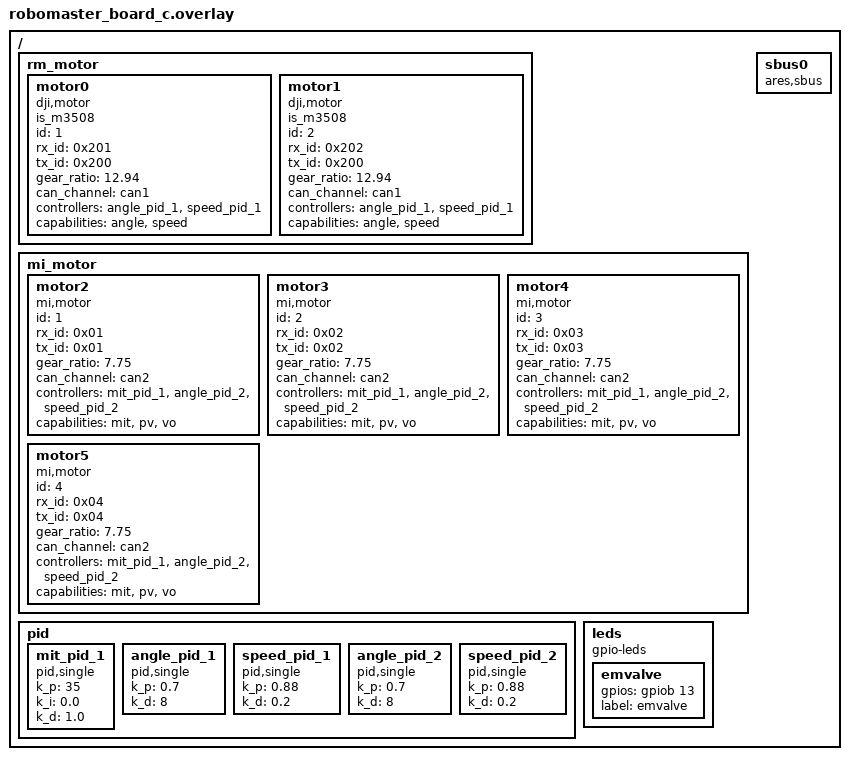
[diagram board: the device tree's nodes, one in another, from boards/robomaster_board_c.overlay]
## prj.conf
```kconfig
# 启用线程分析器
CONFIG_THREAD_ANALYZER=y
CONFIG_THREAD_ANALYZER_USE_LOG=y
CONFIG_THREAD_ANALYZER_USE_PRINTK=n
CONFIG_THREAD_NAME=y
# CONFIG_THREAD_ANALYZER_AUTO=y
# CONFIG_THREAD_ANALYZER_AUTO_INTERVAL=5
CONFIG_THREAD_ANALYZER_LOG_LEVEL_INF=y
CONFIG_THREAD_ANALYZER_AUTO_SEPARATE_CORES=n

# 启用 Shell 支持
CONFIG_SHELL=n
CONFIG_SHELL_BACKENDS=n
CONFIG_SHELL_BACKEND_SERIAL=n

# 启用 UART 控制台
CONFIG_UART_CONSOLE=y

# 禁用 SEGGER RTT
CONFIG_USE_SEGGER_RTT=n

# 启用事件支持
CONFIG_EVENTS=y

# 启用控制台支持
CONFIG_CONSOLE=y

# 启用串行支持
CONFIG_SERIAL=y
CONFIG_SPI_ASYNC=y
# 禁用优化
CONFIG_NO_OPTIMIZATIONS=y

# 启用驱动
CONFIG_MOTOR=y
CONFIG_MOTOR_DJI=y
CONFIG_MOTOR_MI=y
CONFIG_MOTOR_LOG_LEVEL=4
CONFIG_CAN=y
CONFIG_MOTOR_INIT_PRIORITY=90
CONFIG_PID=y

CONFIG_ARES=y
CONFIG_ARES_SBUS=y
CONFIG_SBUS_INIT_PRIORITY=90

# use ASYNC uart API
CONFIG_SERIAL=y
CONFIG_UART_ASYNC_API=y
CONFIG_UART_INTERRUPT_DRIVEN=y

CONFIG_DMA=y
CONFIG_DMA_STM32=y  # STM32 DMA 驱动
CONFIG_UART_STM32=y # STM32 UART 驱动
# CONFIG_STM32_UART_DMA=y

# CONFIG_HAS_STM32CUBE=y
# CONFIG_USE_STM32_HAL_DMA=y
# CONFIG_SPI=y
# CONFIG_SPI_STM32=y

#
# Device Drivers
#
# CONFIG_SENSOR=y
# CONFIG_BMI08X=y
# CONFIG_BMI08X_ACCEL_TRIGGER_NONE is not set
# CONFIG_BMI08X_ACCEL_TRIGGER_GLOBAL_THREAD=y
# CONFIG_BMI08X_ACCEL_TRIGGER_OWN_THREAD is not set
# CONFIG_BMI08X_GYRO_TRIGGER_NONE is not set
# CONFIG_BMI08X_GYRO_TRIGGER_GLOBAL_THREAD=y
# CONFIG_BMI08X_GYRO_TRIGGER_OWN_THREAD is not set
# CONFIG_BMI08X_I2C_WRITE_BURST_SIZE=16

CONFIG_DEBUG_THREAD_INFO=y

CONFIG_MAIN_STACK_SIZE=4096
```

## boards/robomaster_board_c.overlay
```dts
/ {
	rm_motor {
		motor0: motor0{
			compatible = "dji,motor";
            is_m3508;
			id = <1>;
            rx_id = <0x201>;
            tx_id = <0x200>;
			gear_ratio = "12.94";
			status = "okay";
			can_channel = <&can1>;
			controllers = <&angle_pid_1 &speed_pid_1>;
			capabilities = "angle", "speed";
		};

		motor1: motor1{
			compatible = "dji,motor";
            is_m3508;
			id = <2>;
            rx_id = <0x202>;
            tx_id = <0x200>;
			gear_ratio = "12.94";
			status = "okay";
			can_channel = <&can1>;
			controllers = <&angle_pid_1 &speed_pid_1>;
			capabilities = "angle", "speed";
		};
	};
	mi_motor{
		motor2: motor2{
			compatible = "mi,motor";
			id = <1>;
            rx_id = <0x01>;
            tx_id = <0x01>;
			gear_ratio = "7.75";
			status = "okay";

			can_channel = <&can2>;
			controllers = <&mit_pid_1 &angle_pid_2 &speed_pid_2>;
			capabilities = "mit", "pv", "vo";
		};
		motor3: motor3{
			compatible = "mi,motor";           
			id = <2>;
            rx_id = <0x02>;
            tx_id = <0x02>;
			gear_ratio = "7.75";
			status = "okay";
			can_channel = <&can2>;
			controllers = <&mit_pid_1 &angle_pid_2 &speed_pid_2>;
			capabilities = "mit", "pv", "vo";
		};
        motor4: motor4{
			compatible = "mi,motor";           
			id = <3>;
            rx_id = <0x03>;
            tx_id = <0x03>;
			gear_ratio = "7.75";
			status = "okay";
			can_channel = <&can2>;
			controllers = <&mit_pid_1 &angle_pid_2 &speed_pid_2>;
			capabilities = "mit", "pv", "vo";
		};
        motor5: motor5{
			compatible = "mi,motor";           
			id = <4>;
            rx_id = <0x04>;
            tx_id = <0x04>;
			gear_ratio = "7.75";
			status = "okay";
			can_channel = <&can2>;
			controllers = <&mit_pid_1 &angle_pid_2 &speed_pid_2>;
			capabilities = "mit", "pv", "vo";
		};
	};

	pid {
		mit_pid_1: mit_pid_1 {
			#controller-cells = <0>;
			compatible = "pid,single";
			k_p = "35";
			k_i = "0.0";
			k_d = "1.0";
		};
		angle_pid_1: angle_pid_1 {
			#controller-cells = <0>;
			compatible = "pid,single";
			k_p = "0.7";
			k_d = "8";
		};
		speed_pid_1: speed_pid_1 {
			#controller-cells = <0>;
			compatible = "pid,single";
			k_p = "0.88";
			k_d = "0.2";
		};
		angle_pid_2: angle_pid_2 {
			#controller-cells = <0>;
			compatible = "pid,single";
			k_p = "0.7";
			k_d = "8";
		};
		speed_pid_2: speed_pid_2 {
			#controller-cells = <0>;
			compatible = "pid,single";
			k_p = "0.88";
			k_d = "0.2";
		};
	};

leds {
    compatible = "gpio-leds";
    emvalve: emvalve {
        gpios = <&gpiob 13 GPIO_ACTIVE_HIGH>;
        label = "emvalve";
    };
};

	sbus0: sbus0 {
		compatible = "ares,sbus";
		status = "okay";
	};
};
```

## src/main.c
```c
#include "ares/board/init.h"
#include "ares/ares_comm.h"
#include <ares/protocol/dual/dual_protocol.h>
#include <ares/interface/usb/usb_bulk.h>
#include "R2_devices.h"
#include "five_linkage.h"
#include <stdbool.h>
#include <stddef.h>
#include <stdint.h>
#include <stdio.h>
#include <math.h>
#include <zephyr/logging/log.h>
#include <zephyr/devicetree.h>
#include <zephyr/drivers/can.h>
#include <zephyr/debug/thread_analyzer.h>
#include <zephyr/kernel.h>
#include <zephyr/sys/printk.h>
#include <zephyr/drivers/uart.h>
#include <zephyr/drivers/motor.h>
#include <zephyr/drivers/sbus.h>
#include <zephyr/drivers/sensor.h>

LOG_MODULE_REGISTER(main, LOG_LEVEL_DBG);

#define HIGH_BYTE(x) ((x) >> 8)
#define LOW_BYTE(x) ((x)&0xFF)
#define COMBINE_HL8(HIGH, LOW) ((HIGH << 8) + LOW)

struct k_thread feedback_thread_data;
k_tid_t feedback_tid = 0;
K_THREAD_STACK_DEFINE(feedback_stack_area, 4096);



Five link;

float Coordinates[2] = {0.0f, 0.0f}; //末端坐标

void rx_cb(void) {
    // 简单验证
    if (!isfinite(Coordinates[0]) || !isfinite(Coordinates[1])) {
        LOG_ERR("Invalid coordinates received");
        return;
    }
    
    // 执行控制
    go_to_position(&link, Coordinates[0], Coordinates[1]);
    
    // 日志输出（可选择降低频率）
    LOG_DBG("Coordinates: x=%.1f, y=%.1f", Coordinates[0], Coordinates[1]);
}

ARES_BULK_INTERFACE_DEFINE(usb_bulk_interface);
DUAL_PROPOSE_PROTOCOL_DEFINE(dual_protocol);
int main()
{ 

  five_init(&link, 230.0, 270.0, 270.0, 230.0, 200.0);
  ares_bind_interface(&usb_bulk_interface, &dual_protocol);

  dual_sync_add(&dual_protocol, 0x4004, (uint8_t *)Coordinates, sizeof(Coordinates), rx_cb);


  motor_set_mode(motor5,MIT);
  k_msleep(1);
  motor_set_mode(motor6,MIT);

  init_position();//电机编码初始化
  k_msleep(500);

  while(1)
  {
    k_msleep(1);
  }
}
```

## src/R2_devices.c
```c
#include "R2_devices.h"

const struct device *motor1 = DEVICE_DT_GET(MOTOR1_NODE);//3508
const struct device *motor2 = DEVICE_DT_GET(MOTOR2_NODE);//3508
const struct device *motor3 = DEVICE_DT_GET(MOTOR3_NODE);//运球mi
const struct device *motor4 = DEVICE_DT_GET(MOTOR4_NODE);//运球mi
const struct device *motor5 = DEVICE_DT_GET(MOTOR5_NODE);//五连杆mi
const struct device *motor6 = DEVICE_DT_GET(MOTOR6_NODE);//五连杆mi
const struct device *sbus = DEVICE_DT_GET(SBUS_NODE);
const struct gpio_dt_spec emvalve = GPIO_DT_SPEC_GET_BY_IDX(DT_NODELABEL(emvalve), gpios, 0);
```

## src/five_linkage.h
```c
#ifndef FIVE_LINKAGE_H
#define FIVE_LINKAGE_H

#include <math.h>
#include <zephyr/drivers/motor.h>
#include <zephyr/kernel.h>
#include <zephyr/logging/log.h>

// 五连杆相关常量定义
#define G 9.80665f
#define M_PI 3.14159265358979323846f
#define orig_angle_1 163.35f  // 电机1的限位角度
#define orig_angle_2 139.59f  // 电机2的限位角度
#define angle_range 113.23f   // 电机的总限位角度
#define IK_EPSILON 1e-9

// 五连杆数据结构
typedef struct {
    float l1, l2, l3, l4, l5;
    float X_C, Y_C;
} Five; // 五连杆参数

// 辅助点结构
typedef struct { 
    double x, y; 
} Point;

// 全局变量声明
extern float phi1, phi2, phi3, phi4;
extern float last_target_angle1, last_target_angle2;

// 五连杆函数声明
/**
 * @brief 五连杆初始化
 * @param link 五连杆参数
 * @param l1 连杆1长度
 * @param l2 连杆2长度
 * @param l3 连杆3长度
 * @param l4 连杆4长度
 * @param l5 连杆5长度
 */
void five_init(Five *link, float l1, float l2, float l3, float l4, float l5);

/**
 * @brief 更新末端坐标
 * @param link 五连杆参数
 * @param X 末端坐标 X
 * @param Y 末端坐标 Y
 */
void update_position(Five *link, float X, float Y);

/**
 * @brief 五连杆逆运动学解算
 * @param link 五连杆参数, 包含以 l5 中点为原点的末端坐标 (X_C, Y_C)
 * @param phi1 输出: 电机1 (左) 的角度 (rad)
 * @param phi2 输出: 连杆1和2之间的夹角 (rad)
 * @param phi3 输出: 连杆4和3之间的夹角 (rad)
 * @param phi4 输出: 电机2 (右) 的角度 (rad)
 */
void inverse_kinematics(Five *link, float *phi1, float *phi2, float *phi3, float *phi4);

/**
 * @brief 检查角度是否合理
 * @param angle_1 角度1指针
 * @param angle_2 角度2指针
 */
void range_check(float* angle_1, float* angle_2);

/**
 * @brief 五连杆电机位置初始化
 */
void init_position(void);

/**
 * @brief 电机位置控制
 * @param link 五连杆参数
 * @param X 末端坐标 X
 * @param Y 末端坐标 Y
 */
void go_to_position(Five *link, float X, float Y);

// 辅助函数声明
/**
 * @brief 计算两点间距离的平方
 */
double distSq(Point p1, Point p2);

/**
 * @brief 计算两圆交点
 */
int get_circle_intersections(Point p1, double r1, Point p2, double r2, Point* i1, Point* i2);

/**
 * @brief 角度归一化
 */
double normalize_angle(double angle);

#endif // FIVE_LINKAGE_H
```
